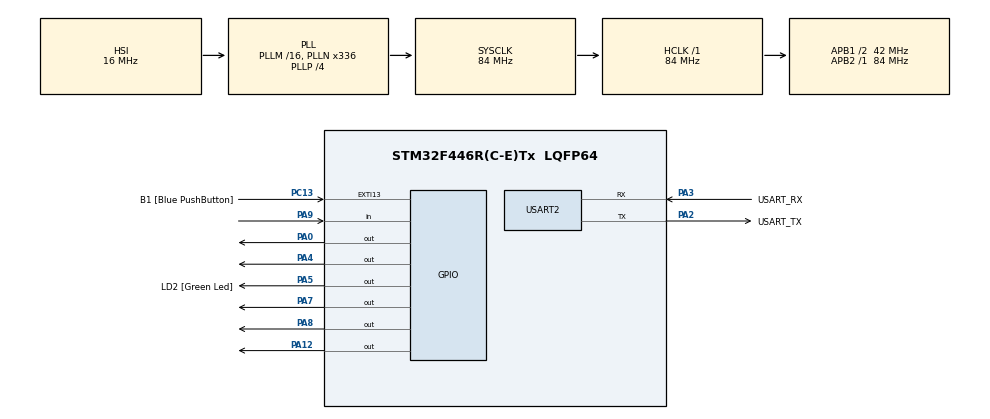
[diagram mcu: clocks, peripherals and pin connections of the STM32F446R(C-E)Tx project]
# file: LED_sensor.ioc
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Mcu.Family=STM32F4
Mcu.Name=STM32F446R(C-E)Tx
Mcu.Package=LQFP64
NVIC.PriorityGroup=NVIC_PRIORITYGROUP_0
PA0-WKUP.Signal=GPIO_Output
PA12.Signal=GPIO_Output
PA13.GPIO_Label=TMS
PA13.Mode=Serial_Wire
PA13.Signal=SYS_JTMS-SWDIO
PA14.GPIO_Label=TCK
PA14.Mode=Serial_Wire
PA14.Signal=SYS_JTCK-SWCLK
PA2.GPIO_Label=USART_TX
PA2.Mode=Asynchronous
PA2.Signal=USART2_TX
PA3.GPIO_Label=USART_RX
PA3.Mode=Asynchronous
PA3.Signal=USART2_RX
PA4.Signal=GPIO_Output
PA5.GPIO_Label=LD2 [Green Led]
PA5.Signal=GPIO_Output
PA7.Signal=GPIO_Output
PA8.Signal=GPIO_Output
PA9.Signal=GPIO_Input
PB3.GPIO_Label=SWO
PB3.Signal=SYS_JTDO-SWO
PC13.GPIO_Label=B1 [Blue PushButton]
PC13.GPIO_ModeDefaultEXTI=GPIO_MODE_IT_FALLING
PC13.Signal=GPXTI13
PC14-OSC32_IN.Mode=LSE-External-Oscillator
PC14-OSC32_IN.Signal=RCC_OSC32_IN
PC15-OSC32_OUT.Mode=LSE-External-Oscillator
PC15-OSC32_OUT.Signal=RCC_OSC32_OUT
PH0-OSC_IN.Mode=HSE-External-Oscillator
PH0-OSC_IN.Signal=RCC_OSC_IN
PH1-OSC_OUT.Mode=HSE-External-Oscillator
PH1-OSC_OUT.Signal=RCC_OSC_OUT
ProjectManager.HeapSize=0x200
ProjectManager.StackSize=0x400
ProjectManager.TargetToolchain=STM32CubeIDE
RCC.48MHZClocksFreq_Value=84000000
RCC.AHBFreq_Value=84000000
RCC.APB1CLKDivider=RCC_HCLK_DIV2
RCC.APB1Freq_Value=42000000
RCC.APB1TimFreq_Value=84000000
RCC.APB2Freq_Value=84000000
RCC.APB2TimFreq_Value=84000000
RCC.CortexFreq_Value=84000000
RCC.FLatency-AdvancedSettings=FLASH_LATENCY_2
RCC.HCLKFreq_Value=84000000
RCC.HSE_VALUE=8000000
RCC.HSI_VALUE=16000000
RCC.PLLN=336
RCC.PLLP=RCC_PLLP_DIV4
RCC.SYSCLKFreq_VALUE=84000000
RCC.SYSCLKSource=RCC_SYSCLKSOURCE_PLLCLK
RCC.USBFreq_Value=168000000
RCC.VCOOutputFreq_Value=336000000
USART2.VirtualMode=VM_ASYNC
VP_TIM4_VS_ClockSourceINT.Mode=Internal
board=NUCLEO-F446RE

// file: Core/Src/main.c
/* USER CODE BEGIN Header */
/**
  ******************************************************************************
  * @file           : main.c
  * @brief          : Main program body
  ******************************************************************************
  * @attention
  *
  * Copyright (c) 2025 STMicroelectronics.
  * All rights reserved.
  *
  * This software is licensed under terms that can be found in the LICENSE file
  * in the root directory of this software component.
  * If no LICENSE file comes with this software, it is provided AS-IS.
  *
  ******************************************************************************
  */
/* USER CODE END Header */
#include "main.h"
#include <stdio.h>
#include "led.h"
#include <string.h>

TIM_HandleTypeDef htim4;

UART_HandleTypeDef huart2;

void SystemClock_Config(void);
static void MX_GPIO_Init(void);
static void MX_USART2_UART_Init(void);
static void MX_TIM4_Init(void);
/* USER CODE BEGIN PFP */
void HCSR04_Trigger(void);
uint32_t HCSR04_Read(void);
void UART2_SendString(const char *str);
/* USER CODE END PFP */

int main(void)
{

  /* MCU Configuration--------------------------------------------------------*/

  /* Reset of all peripherals, Initializes the Flash interface and the Systick. */
  HAL_Init();

  /* Configure the system clock */
  SystemClock_Config();

  /* Initialize all configured peripherals */
  MX_GPIO_Init();
  LED_Init();
  MX_USART2_UART_Init();
  MX_TIM4_Init();
  HAL_TIM_Base_Start(&htim4);

  CoreDebug->DEMCR |= CoreDebug_DEMCR_TRCENA_Msk;
  DWT->CTRL |= DWT_CTRL_CYCCNTENA_Msk;

  /* Infinite loop */
  char buffer[50];
  uint32_t pulse_duration, distance;
  while (1)
  {
      HCSR04_Trigger();
      pulse_duration = HCSR04_Read(); // in us
      distance = (pulse_duration * 343) / (2 * 10000); // cm

      if (distance > 13|| distance == 0) {
          sprintf(buffer, "Out of range\r\n");
      } else {
          sprintf(buffer, "Distance: %lu cm\r\n",distance);

      }
      if (distance <= 4) {
          LED_On(PIN0);
          LED_On(PIN4);
          LED_On(PIN7);
          LED_On(PIN12);
      }
      else if (distance <= 7) {
          LED_On(PIN0);
          LED_On(PIN4);
          LED_On(PIN7);
          LED_Off(PIN12);
      }
      else if (distance <= 9) {
          LED_On(PIN0);
          LED_On(PIN4);
          LED_Off(PIN7);
          LED_Off(PIN12);
      }
      else if (distance <= 12){
          LED_On(PIN0);
          LED_Off(PIN4);
          LED_Off(PIN7);
          LED_Off(PIN12);
      }
      else{
    	  LED_Off(PIN0);
    	  LED_Off(PIN4);
    	  LED_Off(PIN7);
    	  LED_Off(PIN12);

      }
      UART2_SendString(buffer);
      HAL_Delay(500);
  }

  /* USER CODE END 3 */
}

void delay_us(uint32_t us)
{
    uint32_t start = DWT->CYCCNT;
    us *= (HAL_RCC_GetHCLKFreq() / 1000000);
    while ((DWT->CYCCNT - start) < us);
}

void HCSR04_Trigger(void)
{
    HAL_GPIO_WritePin(GPIOA, GPIO_PIN_8, GPIO_PIN_SET);
    delay_us(10);
    HAL_GPIO_WritePin(GPIOA, GPIO_PIN_8, GPIO_PIN_RESET);
}

uint32_t HCSR04_Read(void)
{
    uint32_t timeout = 30000; // 30 ms timeout

    // Wait for Echo pin to go HIGH
    while (HAL_GPIO_ReadPin(GPIOA, GPIO_PIN_9) == GPIO_PIN_RESET)
    {
        if (--timeout == 0) return 0;
    }

    __HAL_TIM_SET_COUNTER(&htim4, 0);

    timeout = 30000;
    // Wait for Echo pin to go LOW
    while (HAL_GPIO_ReadPin(GPIOA, GPIO_PIN_9) == GPIO_PIN_SET)
    {
        if (--timeout == 0) return 0;
    }

    return __HAL_TIM_GET_COUNTER(&htim4);
}

void UART2_SendString(const char *str)
{
    HAL_UART_Transmit(&huart2, (uint8_t *)str, strlen(str), HAL_MAX_DELAY);
}

void SystemClock_Config(void)
{
  RCC_OscInitTypeDef RCC_OscInitStruct = {0};
  RCC_ClkInitTypeDef RCC_ClkInitStruct = {0};

  /** Configure the main internal regulator output voltage
  */
  __HAL_RCC_PWR_CLK_ENABLE();
  __HAL_PWR_VOLTAGESCALING_CONFIG(PWR_REGULATOR_VOLTAGE_SCALE3);

  /** Initializes the RCC Oscillators according to the specified parameters
  * in the RCC_OscInitTypeDef structure.
  */
  RCC_OscInitStruct.OscillatorType = RCC_OSCILLATORTYPE_HSI;
  RCC_OscInitStruct.HSIState = RCC_HSI_ON;
  RCC_OscInitStruct.HSICalibrationValue = RCC_HSICALIBRATION_DEFAULT;
  RCC_OscInitStruct.PLL.PLLState = RCC_PLL_ON;
  RCC_OscInitStruct.PLL.PLLSource = RCC_PLLSOURCE_HSI;
  RCC_OscInitStruct.PLL.PLLM = 16;
  RCC_OscInitStruct.PLL.PLLN = 336;
  RCC_OscInitStruct.PLL.PLLP = RCC_PLLP_DIV4;
  RCC_OscInitStruct.PLL.PLLQ = 2;
  RCC_OscInitStruct.PLL.PLLR = 2;
  if (HAL_RCC_OscConfig(&RCC_OscInitStruct) != HAL_OK)
  {
    Error_Handler();
  }

  /** Initializes the CPU, AHB and APB buses clocks
  */
  RCC_ClkInitStruct.ClockType = RCC_CLOCKTYPE_HCLK|RCC_CLOCKTYPE_SYSCLK
                              |RCC_CLOCKTYPE_PCLK1|RCC_CLOCKTYPE_PCLK2;
  RCC_ClkInitStruct.SYSCLKSource = RCC_SYSCLKSOURCE_PLLCLK;
  RCC_ClkInitStruct.AHBCLKDivider = RCC_SYSCLK_DIV1;
  RCC_ClkInitStruct.APB1CLKDivider = RCC_HCLK_DIV2;
  RCC_ClkInitStruct.APB2CLKDivider = RCC_HCLK_DIV1;

  if (HAL_RCC_ClockConfig(&RCC_ClkInitStruct, FLASH_LATENCY_2) != HAL_OK)
  {
    Error_Handler();
  }
}

static void MX_TIM4_Init(void)
{

  TIM_ClockConfigTypeDef sClockSourceConfig = {0};
  TIM_MasterConfigTypeDef sMasterConfig = {0};

  htim4.Instance = TIM4;
  htim4.Init.Prescaler = 83;
  htim4.Init.CounterMode = TIM_COUNTERMODE_UP;
  htim4.Init.Period = 65535;
  htim4.Init.ClockDivision = TIM_CLOCKDIVISION_DIV1;
  htim4.Init.AutoReloadPreload = TIM_AUTORELOAD_PRELOAD_DISABLE;
  if (HAL_TIM_Base_Init(&htim4) != HAL_OK)
  {
    Error_Handler();
  }
  sClockSourceConfig.ClockSource = TIM_CLOCKSOURCE_INTERNAL;
  if (HAL_TIM_ConfigClockSource(&htim4, &sClockSourceConfig) != HAL_OK)
  {
    Error_Handler();
  }
  sMasterConfig.MasterOutputTrigger = TIM_TRGO_RESET;
  sMasterConfig.MasterSlaveMode = TIM_MASTERSLAVEMODE_DISABLE;
  if (HAL_TIMEx_MasterConfigSynchronization(&htim4, &sMasterConfig) != HAL_OK)
  {
    Error_Handler();
  }

}

static void MX_USART2_UART_Init(void)
{

  huart2.Instance = USART2;
  huart2.Init.BaudRate = 115200;
  huart2.Init.WordLength = UART_WORDLENGTH_8B;
  huart2.Init.StopBits = UART_STOPBITS_1;
  huart2.Init.Parity = UART_PARITY_NONE;
  huart2.Init.Mode = UART_MODE_TX_RX;
  huart2.Init.HwFlowCtl = UART_HWCONTROL_NONE;
  huart2.Init.OverSampling = UART_OVERSAMPLING_16;
  if (HAL_UART_Init(&huart2) != HAL_OK)
  {
    Error_Handler();
  }

}

static void MX_GPIO_Init(void)
{
  GPIO_InitTypeDef GPIO_InitStruct = {0};

  /* GPIO Ports Clock Enable */
  __HAL_RCC_GPIOC_CLK_ENABLE();
  __HAL_RCC_GPIOH_CLK_ENABLE();
  __HAL_RCC_GPIOA_CLK_ENABLE();
  __HAL_RCC_GPIOB_CLK_ENABLE();

  /*Configure GPIO pin Output Level */
  HAL_GPIO_WritePin(GPIOA, LD2_Pin|GPIO_PIN_8, GPIO_PIN_RESET);

  /*Configure GPIO pin : B1_Pin */
  GPIO_InitStruct.Pin = B1_Pin;
  GPIO_InitStruct.Mode = GPIO_MODE_IT_FALLING;
  GPIO_InitStruct.Pull = GPIO_NOPULL;
  HAL_GPIO_Init(B1_GPIO_Port, &GPIO_InitStruct);

  /*Configure GPIO pins : LD2_Pin PA8 */
  GPIO_InitStruct.Pin = LD2_Pin|GPIO_PIN_8;
  GPIO_InitStruct.Mode = GPIO_MODE_OUTPUT_PP;
  GPIO_InitStruct.Pull = GPIO_NOPULL;
  GPIO_InitStruct.Speed = GPIO_SPEED_FREQ_LOW;
  HAL_GPIO_Init(GPIOA, &GPIO_InitStruct);

  /*Configure GPIO pin : PA9 */
  GPIO_InitStruct.Pin = GPIO_PIN_9;
  GPIO_InitStruct.Mode = GPIO_MODE_INPUT;
  GPIO_InitStruct.Pull = GPIO_NOPULL;
  HAL_GPIO_Init(GPIOA, &GPIO_InitStruct);

}

void Error_Handler(void)
{
  __disable_irq();
  while (1)
  {
  }
}
